# NUC029AE_v1 register map
File version: 1.0
Registers are 32-bit, read-write, reset 0x0 unless marked. A register's access mark holds for its fields unless they carry their own. Offsets are from the block's base; [hi:lo] are bit positions; 'fields as' and 'values as' point back to an identical list.

## ACMP — ACMP Register Map
Base 0x400D0000
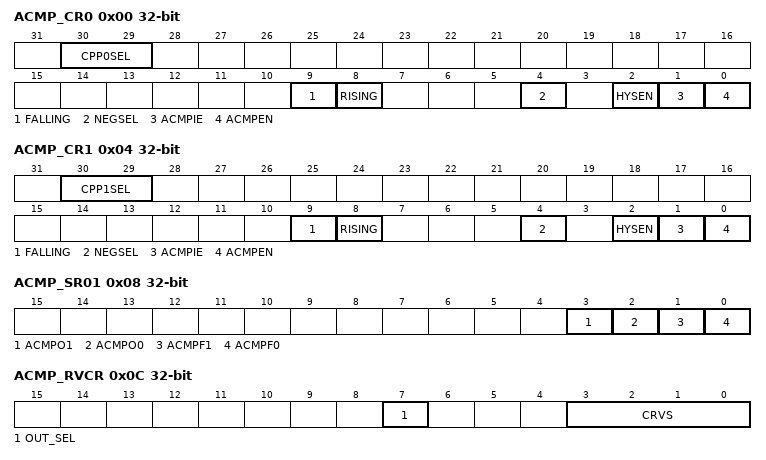
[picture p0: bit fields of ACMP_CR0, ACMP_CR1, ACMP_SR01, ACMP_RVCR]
0x00 ACMP_CR0 — Analog Comparator 0 Control Register
  [30:29] CPP0SEL — Analog Comparator 0 Positive Input Selection
    0=CPP0 is from P1.5 pin; 1=CPP0 is from P1.0 pin; 2=CPP0 is from P1.2 pin; 3=CPP0 is from P1.3 pin
  [9] FALLING — Analog Comparator 0 Falling Edge Trigger Enable Control. Note: The bit is only effective while analog comparator 0 triggers PWM or Timer.
    0=Analog comparator 0 falling edge trigger PWM or Timer Enabled; 1=Analog comparator 0 falling edge trigger Disabled
  [8] RISING — Analog Comparator 0 Rising Edge Trigger Enable Control. Note: The bit is only effective while analog comparator 0 triggers PWM or Timer.
    0=Analog comparator 0 rising edge trigger PWM or Timer Enabled; 1=Analog comparator 0 rising edge trigger Disabled
  [4] NEGSEL — Analog Comparator 0 Negative Input Selection
    0=The source of the negative comparator input is from CPN0 pin; 1=The source of the negative comparator input is from internal band-gap voltage or comparator reference voltage
  [2] HYSEN — Analog Comparator 0 Hysteresis Enable Control
    0=Hysteresis function Disabled; 1=Hysteresis function Enabled
  [1] ACMPIE — Analog Comparator 0 Interrupt Enable Control
    0=Interrupt function Disabled; 1=Interrupt function Enabled
  [0] ACMPEN — Analog Comparator 0 Enable Control. Note: Analog comparator output needs to wait 2 us stable time after this bit is set.
    0=Analog Comparator 0 Disabled; 1=Analog Comparator 1 Enabled
0x04 ACMP_CR1 — Analog Comparator 1 Control Register
  [30:29] CPP1SEL — Analog Comparator 1 Positive Input Selection
    0=CPP1 is from P3.1 pin; 1=CPP1 is from P3.2 pin; 2=CPP1 is from P3.4 pin; 3=CPP1 is from P3.5 pin
  [9] FALLING — Analog Comparator 1 Falling Edge Trigger Enable Control. Note: The bit is only effective while analog comparator 1 triggers PWM or Timer.
    0=Analog comparator 1 falling edge trigger PWM or Timer Enabled; 1=Analog comparator 1 falling edge trigger Disabled
  [8] RISING — Analog Comparator 1 Rising Edge Trigger Enable Control. Note: The bit is only effective while analog comparator 1 triggers PWM or Timer.
    0=Analog comparator 1 rising edge trigger PWM or Timer Enabled; 1=Analog comparator 1 rising edge trigger Disabled
  [4] NEGSEL — Analog Comparator 1 Negative Input Selection
    0=The source of the negative comparator input is from CPN1 pin; 1=The source of the negative comparator input is from internal band-gap voltage or comparator reference voltage
  [2] HYSEN — Analog Comparator 1 Hysteresis Enable Control
    values as ACMP_CR0.HYSEN
  [1] ACMPIE — Analog Comparator 1 Interrupt Enable Control
    0=Interrupt function Disabled; 1=Interrupt function Enabled
  [0] ACMPEN — Analog Comparator 1 Enable Control. Note: Analog comparator output needs to wait 2 us stable time after this bit is set.
    0=Analog Comparator 1 Disabled; 1=Analog Comparator 1 Enabled
0x08 ACMP_SR01 — Analog Comparator 0/1 Status Register
  [3] ACMPO1 — Analog Comparator 1 Output
    0=Analog comparator 1 outputs 0; 1=Analog comparator 1 outputs 1
  [2] ACMPO0 — Analog Comparator 0 Output
    0=Analog comparator 0 outputs 0; 1=Analog comparator 0 outputs 1
  [1] ACMPF1 — Analog Comparator 1 Flag. Note: Software can write 1 to clear this bit to 0.
    0=Analog comparator 1 output does not change; 1=Analog comparator 1 output changed
  [0] ACMPF0 — Analog Comparator 0 Flag. Note: Software can write 1 to clear this bit to 0.
    0=Analog comparator 0 output does not change; 1=Analog comparator 0 output changed
0x0C ACMP_RVCR — Analog Comparator Reference Voltage Control Register
  [7] OUT_SEL — CRV Module Output Selection
    0=Band-gap voltage; 1=Internal comparator reference voltage
  [3:0] CRVS — Comparator Reference Voltage Setting

## WDT — WDT Register Map
Base 0x40004000
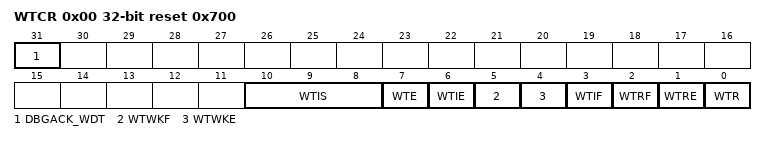
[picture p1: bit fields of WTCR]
0x00 WTCR reset 0x700 — Watchdog Timer Control Register
  [31] DBGACK_WDT — ICE Debug Mode Acknowledge Disable Control (Write Protect). WDT up counter will keep going no matter CPU is hanging by ICE or not.
    0=ICE debug mode acknowledgement effects WDT counting; 1=ICE debug mode acknowledgement Disabled
  [10:8] WTIS — Watchdog Timer Interval Selection. These three bits select the time-out interval for the Watchdog Timer.
    0=24 * TWDT; 1=26 * TWDT; 2=28 * TWDT; 3=210 * TWDT; 4=212 * TWDT; 5=214 * TWDT; 6=216 * TWDT; 7=218 * TWDT
  [7] WTE — Watchdog Timer Enable Control (Write Protect)
    0=WDT Disabled. (This action will reset the internal up counter value.); 1=WDT Enabled
  [6] WTIE — Watchdog Timer Time-out Interrupt Enable Control (Write Protect). If this bit is enabled, the WDT time-out interrupt signal is generated and inform to CPU.
    0=WDT time-out interrupt Disabled; 1=WDT time-out interrupt Enabled
  [5] WTWKF — Watchdog Timer Time-out Wake-up Flag. This bit indicates the interrupt wake-up flag status of WDT. Note: This bit is cleared by writing 1 to it.
    0=WDT does not cause chip wake-up; 1=Chip wake-up from Idle or Power-down mode if WDT time-out interrupt signal generated
  [4] WTWKE — Watchdog Timer Time-out Wake-up Function Control (Write Protect). If this bit is set to 1, while WTIF is generated to 1 and WTIE enabled, the WDT time-out interrupt signal will generate a wake-up trigger event to chip. Note: Chip can be woken-up by WDT time-out interrupt signal generated only if WDT clock source is selected to 10 kHz oscillator.
    0=Wake-up trigger event Disabled if WDT time-out interrupt signal generated; 1=Wake-up trigger event Enabled if WDT time-out interrupt signal generated
  [3] WTIF — Watchdog Timer Time-out Interrupt Flag. This bit will be set to 1 while WDT up counter value reaches the selected WDT time-out interval. Note: This bit is cleared by writing 1 to it.
    0=WDT time-out interrupt did not occur; 1=WDT time-out interrupt occurred
  [2] WTRF — Watchdog Timer Time-out Reset Flag. This bit indicates the system has been reset by WDT time-out reset or not. Note: This bit is cleared by writing 1 to it.
    0=WDT time-out reset did not occur; 1=WDT time-out reset occurred
  [1] WTRE — Watchdog Timer Time-out Reset Enable Control (Write Protect). Setting this bit will enable the WDT time-out reset function if the WDT up counter value has not been cleared after the specific WDT reset delay period (1024 * TWDT) expires.
    0=WDT time-out reset function Disabled; 1=WDT time-out reset function Enabled
  [0] WTR — Reset Watchdog Timer Up Counter (Write Protect). Note: This bit will be automatically cleared by hardware.
    0=No effect; 1=Reset the internal 18-bit WDT up counter value
